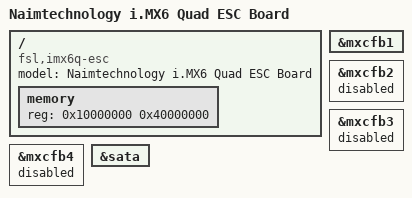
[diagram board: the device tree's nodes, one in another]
/*
 * Copyright 2012=2015 Freescale Semiconductor, Inc.
 * Copyright 2011 Linaro Ltd.
 *
 * The code contained herein is licensed under the GNU General Public
 * License. You may obtain a copy of the GNU General Public License
 * Version 2 or later at the following locations:
 *
 * http://www.opensource.org/licenses/gpl-license.html
 * http://www.gnu.org/copyleft/gpl.html
 */

/dts-v1/;

#include "imx6q.dtsi"
#include "imx6qdl-esc.dtsi"

/ {
	model = "Naimtechnology i.MX6 Quad ESC Board";
	compatible = "fsl,imx6q-esc", "fsl,imx6q";

 	memory { 
 		reg = <0x10000000 0x40000000>; /* reg = 0x10000000 (base address) 0x80000000 (size = 1073741824 bits => 1GB) */ 
 	}; 

};


&mxcfb1 {
	status = "okay";
};

&mxcfb2 {
	status = "disabled";
};

&mxcfb3 {
	status = "disabled";
};

&mxcfb4 {
	status = "disabled";
};

&sata {
	status = "okay";
};
